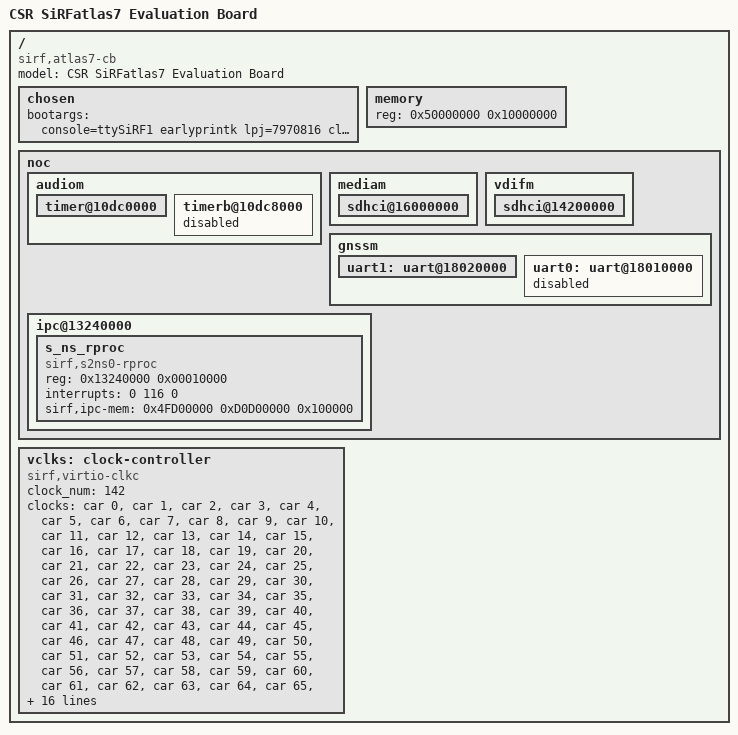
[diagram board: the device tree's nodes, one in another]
/*
 * DTS file for CSR SiRFatlas7 Evaluation Board
 *
 * Copyright (c) 2012 Cambridge Silicon Radio Limited, a CSR plc group company.
 *
 * Licensed under GPLv2 or later.
 */

/dts-v1/;

/include/ "atlas7.dtsi"

/ {
	model = "CSR SiRFatlas7 Evaluation Board";
	compatible = "sirf,atlas7-cb", "sirf,atlas7";

	chosen {
		bootargs = "console=ttySiRF1 earlyprintk lpj=7970816 clk_ignore_unused";
	};

	memory {
		device_type = "memory";
		reg = <0x50000000 0x10000000>; /* 256M for S */
	};

	noc {
		audiom {
			timer@10dc0000 {
				status = "okay";
			};
			timerb@10dc8000 {
				status = "disabled";
			};
		};

	        mediam {
                        sdhci@16000000 {
                                status = "okay";
                        };
                };

                vdifm {
                        sdhci@14200000 {
                                status = "okay";
                        };
                };

                gnssm {
                        uart1: uart@18020000 {
				status = "okay";
                        };

                        uart0: uart@18010000 {
				status = "disabled";
                        };
                };

		ipc@13240000 {
			s_ns_rproc {
				compatible = "sirf,s2ns0-rproc";
				reg = <0x13240000 0x00010000>;
				interrupts = <0 116 0>;

				sirf,ipc-mem = <0x4FD00000 0xD0D00000 0x100000>;
			};
		};
	};

	vclks: clock-controller {
		compatible = "sirf,virtio-clkc";
		#clock-cells = <1>;
		clock_num = <142>;
		clocks = <&car 0>, <&car 1>, <&car 2>, <&car 3>,
		      <&car 4>, <&car 5>, <&car 6>, <&car 7>,
		      <&car 8>, <&car 9>, <&car 10>, <&car 11>,
		      <&car 12>, <&car 13>, <&car 14>, <&car 15>,
		      <&car 16>, <&car 17>, <&car 18>, <&car 19>,
		      <&car 20>, <&car 21>, <&car 22>, <&car 23>,
		      <&car 24>, <&car 25>, <&car 26>, <&car 27>,
		      <&car 28>, <&car 29>, <&car 30>, <&car 31>,
		      <&car 32>, <&car 33>, <&car 34>, <&car 35>,
		      <&car 36>, <&car 37>, <&car 38>, <&car 39>,
		      <&car 40>, <&car 41>, <&car 42>, <&car 43>,
		      <&car 44>, <&car 45>, <&car 46>, <&car 47>,
		      <&car 48>, <&car 49>, <&car 50>, <&car 51>,
		      <&car 52>, <&car 53>, <&car 54>, <&car 55>,
		      <&car 56>, <&car 57>, <&car 58>, <&car 59>,
		      <&car 60>, <&car 61>, <&car 62>, <&car 63>,
		      <&car 64>, <&car 65>, <&car 66>, <&car 67>,
		      <&car 68>, <&car 69>, <&car 70>, <&car 71>,
		      <&car 72>, <&car 73>, <&car 74>, <&car 75>,
		      <&car 76>, <&car 77>, <&car 78>, <&car 79>,
		      <&car 80>, <&car 81>, <&car 82>, <&car 83>,
		      <&car 84>, <&car 85>, <&car 86>, <&car 87>,
		      <&car 88>, <&car 89>, <&car 90>, <&car 91>,
		      <&car 92>, <&car 93>, <&car 94>, <&car 95>,
		      <&car 96>, <&car 97>, <&car 98>, <&car 99>,
		      <&car 100>, <&car 101>, <&car 102>, <&car 103>,
		      <&car 104>, <&car 105>, <&car 106>, <&car 107>,
		      <&car 108>, <&car 109>, <&car 110>, <&car 111>,
		      <&car 112>, <&car 113>, <&car 114>, <&car 115>,
		      <&car 116>, <&car 117>, <&car 118>, <&car 119>,
		      <&car 120>, <&car 121>, <&car 122>, <&car 123>,
		      <&car 124>, <&car 125>, <&car 126>, <&car 127>,
		      <&car 128>, <&car 129>, <&car 130>, <&car 131>,
		      <&car 132>, <&car 133>, <&car 134>, <&car 135>,
		      <&car 136>, <&car 137>, <&car 138>, <&car 139>,
		      <&car 140>, <&car 141>;
       };
};
